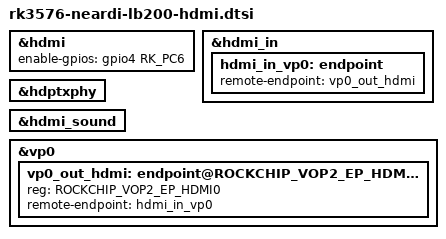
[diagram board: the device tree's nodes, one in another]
// SPDX-License-Identifier: (GPL-2.0+ OR MIT)
/*
 * Neardi LB200 HDMI display (mainline compatible)
 */

#include <dt-bindings/gpio/gpio.h>
#include <dt-bindings/pinctrl/rockchip.h>
#include <dt-bindings/soc/rockchip,vop2.h>

&hdmi {
	status = "okay";
	enable-gpios = <&gpio4 RK_PC6 GPIO_ACTIVE_HIGH>;
};

&hdmi_in {
	hdmi_in_vp0: endpoint {
		remote-endpoint = <&vp0_out_hdmi>;
	};
};

&hdptxphy {
	status = "okay";
};

&hdmi_sound {
	status = "okay";
};

&vp0 {
	vp0_out_hdmi: endpoint@ROCKCHIP_VOP2_EP_HDMI0 {
		reg = <ROCKCHIP_VOP2_EP_HDMI0>;
		remote-endpoint = <&hdmi_in_vp0>;
	};
};
